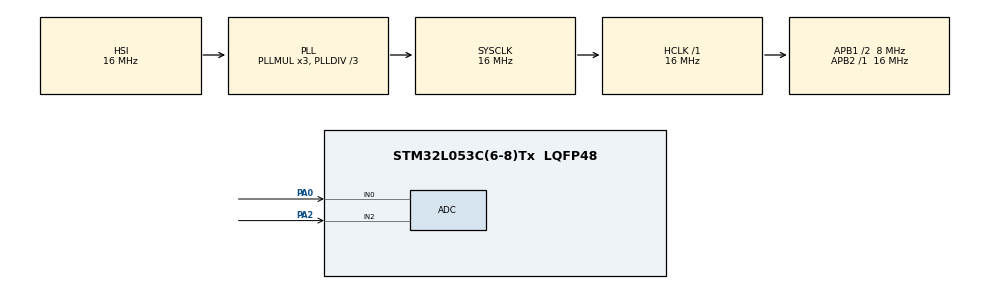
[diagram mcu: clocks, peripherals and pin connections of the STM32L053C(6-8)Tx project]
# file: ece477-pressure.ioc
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Mcu.Family=STM32L0
RCC.MSI_VALUE=2097000
RCC.APB1CLKDivider=RCC_HCLK_DIV2
RCC.SYSCLKSource=RCC_SYSCLKSOURCE_PLLCLK
ProjectManager.StackSize=0x400
RCC.HSI48MClockSelection=RCC_USBCLKSOURCE_HSI48
RCC.HSI16_VALUE=16000000
RCC.PLLDIV=RCC_PLLDIV_3
ProjectManager.TargetToolchain=STM32CubeIDE
RCC.HCLKFreq_Value=16000000
RCC.APB2TimFreq_Value=16000000
RCC.LSE_VALUE=32768
RCC.AHBFreq_Value=16000000
RCC.HSE_VALUE=8000000
board=STM32L0538-DISCO
RCC.VCOOutputFreq_Value=48000000
RCC.APB2Freq_Value=16000000
RCC.RTCClockSelectionVirtual=RCC_RTCCLKSOURCE_LSE
PA0.Mode=IN0
Mcu.Name=STM32L053C(6-8)Tx
PA2.Signal=ADC_IN2
PA0.Signal=ADC_IN0
RCC.SYSCLKFreq_VALUE=16000000
Mcu.Package=LQFP48
ProjectManager.HeapSize=0x200
RCC.HSI_VALUE=16000000
RCC.APB1TimFreq_Value=16000000
PA2.Mode=IN2
RCC.APB1Freq_Value=8000000
RCC.HSI48_VALUE=48000000

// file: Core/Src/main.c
/* USER CODE BEGIN Header */
/**
  ******************************************************************************
  * @file           : main.c
  * @brief          : Main program body
  ******************************************************************************
  * @attention
  *
  * <h2><center>&copy; Copyright (c) 2021 STMicroelectronics.
  * All rights reserved.</center></h2>
  *
  * This software component is licensed by ST under BSD 3-Clause license,
  * the "License"; You may not use this file except in compliance with the
  * License. You may obtain a copy of the License at:
  *                        opensource.org/licenses/BSD-3-Clause
  *
  ******************************************************************************
  */
/* USER CODE END Header */
#include "main.h"
#include "adc.h"
#include "gpio.h"

void SystemClock_Config(void);

int main(void)
{

  /* MCU Configuration--------------------------------------------------------*/

  /* Reset of all peripherals, Initializes the Flash interface and the Systick. */
  HAL_Init();

  /* Configure the system clock */
  SystemClock_Config();

  /* Initialize all configured peripherals */
  MX_GPIO_Init();
  MX_ADC_Init();

  /* Infinite loop */
  /* USER CODE BEGIN WHILE */
  uint16_t pressure = 0;
  uint16_t methane = 0;
  //uint16_t check = 0;

  while(1){
	  ADC1->CHSELR = ADC_CHSELR_CHSEL0;
	  HAL_ADC_Start(&hadc);
	  HAL_ADC_PollForConversion(&hadc, HAL_MAX_DELAY);
	  pressure = HAL_ADC_GetValue(&hadc);
	  HAL_ADC_Stop(&hadc);

	  //if(HAL_ADC_Start(&hadc1) == HAL_OK){
		  //check = 1;
	  //}
	  //if (HAL_ADC_PollForConversion(&hadc1, HAL_MAX_DELAY) == HAL_OK){
	      //raw = HAL_ADC_GetValue(&hadc1);
	  //}

	  ADC1->CHSELR = ADC_CHSELR_CHSEL2;
	  HAL_ADC_Start(&hadc);
	  HAL_ADC_PollForConversion(&hadc, HAL_MAX_DELAY);
	  methane = HAL_ADC_GetValue(&hadc);
	  HAL_ADC_Stop(&hadc);

    /* USER CODE END WHILE */

  }
}

void SystemClock_Config(void)
{
  RCC_OscInitTypeDef RCC_OscInitStruct = {0};
  RCC_ClkInitTypeDef RCC_ClkInitStruct = {0};

  /** Configure the main internal regulator output voltage
  */
  __HAL_PWR_VOLTAGESCALING_CONFIG(PWR_REGULATOR_VOLTAGE_SCALE1);
  /** Initializes the RCC Oscillators according to the specified parameters
  * in the RCC_OscInitTypeDef structure.
  */
  RCC_OscInitStruct.OscillatorType = RCC_OSCILLATORTYPE_HSI;
  RCC_OscInitStruct.HSIState = RCC_HSI_ON;
  RCC_OscInitStruct.HSICalibrationValue = RCC_HSICALIBRATION_DEFAULT;
  RCC_OscInitStruct.PLL.PLLState = RCC_PLL_ON;
  RCC_OscInitStruct.PLL.PLLSource = RCC_PLLSOURCE_HSI;
  RCC_OscInitStruct.PLL.PLLMUL = RCC_PLLMUL_3;
  RCC_OscInitStruct.PLL.PLLDIV = RCC_PLLDIV_3;
  if (HAL_RCC_OscConfig(&RCC_OscInitStruct) != HAL_OK)
  {
    Error_Handler();
  }
  /** Initializes the CPU, AHB and APB buses clocks
  */
  RCC_ClkInitStruct.ClockType = RCC_CLOCKTYPE_HCLK|RCC_CLOCKTYPE_SYSCLK
                              |RCC_CLOCKTYPE_PCLK1|RCC_CLOCKTYPE_PCLK2;
  RCC_ClkInitStruct.SYSCLKSource = RCC_SYSCLKSOURCE_PLLCLK;
  RCC_ClkInitStruct.AHBCLKDivider = RCC_SYSCLK_DIV1;
  RCC_ClkInitStruct.APB1CLKDivider = RCC_HCLK_DIV2;
  RCC_ClkInitStruct.APB2CLKDivider = RCC_HCLK_DIV1;

  if (HAL_RCC_ClockConfig(&RCC_ClkInitStruct, FLASH_LATENCY_0) != HAL_OK)
  {
    Error_Handler();
  }
}

void Error_Handler(void)
{
  __disable_irq();
  while (1)
  {
  }
}

/************************ (C) COPYRIGHT STMicroelectronics *****END OF FILE****/
